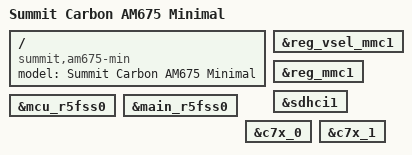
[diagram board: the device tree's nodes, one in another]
// SPDX-License-Identifier: GPL-2.0-or-later OR MIT
/*
 * Copyright 2024 Ezurio LLC
 *
 */

/dts-v1/;

#include "k3-am675-carbon-som.dtsi"

/ {
	model = "Summit Carbon AM675 Minimal";
	compatible = "summit,am675-min", "ti,j722s";
};

&reg_vsel_mmc1 {
	status = "okay";
};

&reg_mmc1 {
	status = "okay";
};

&sdhci1 { /* SDIO_A uSD / M.2_SDIO */
	status = "okay";
};

&mcu_r5fss0 {
	status = "okay";
};

&main_r5fss0 {
	status = "okay";
};

&c7x_0 {
	status = "okay";
};

&c7x_1 {
	status = "okay";
};
